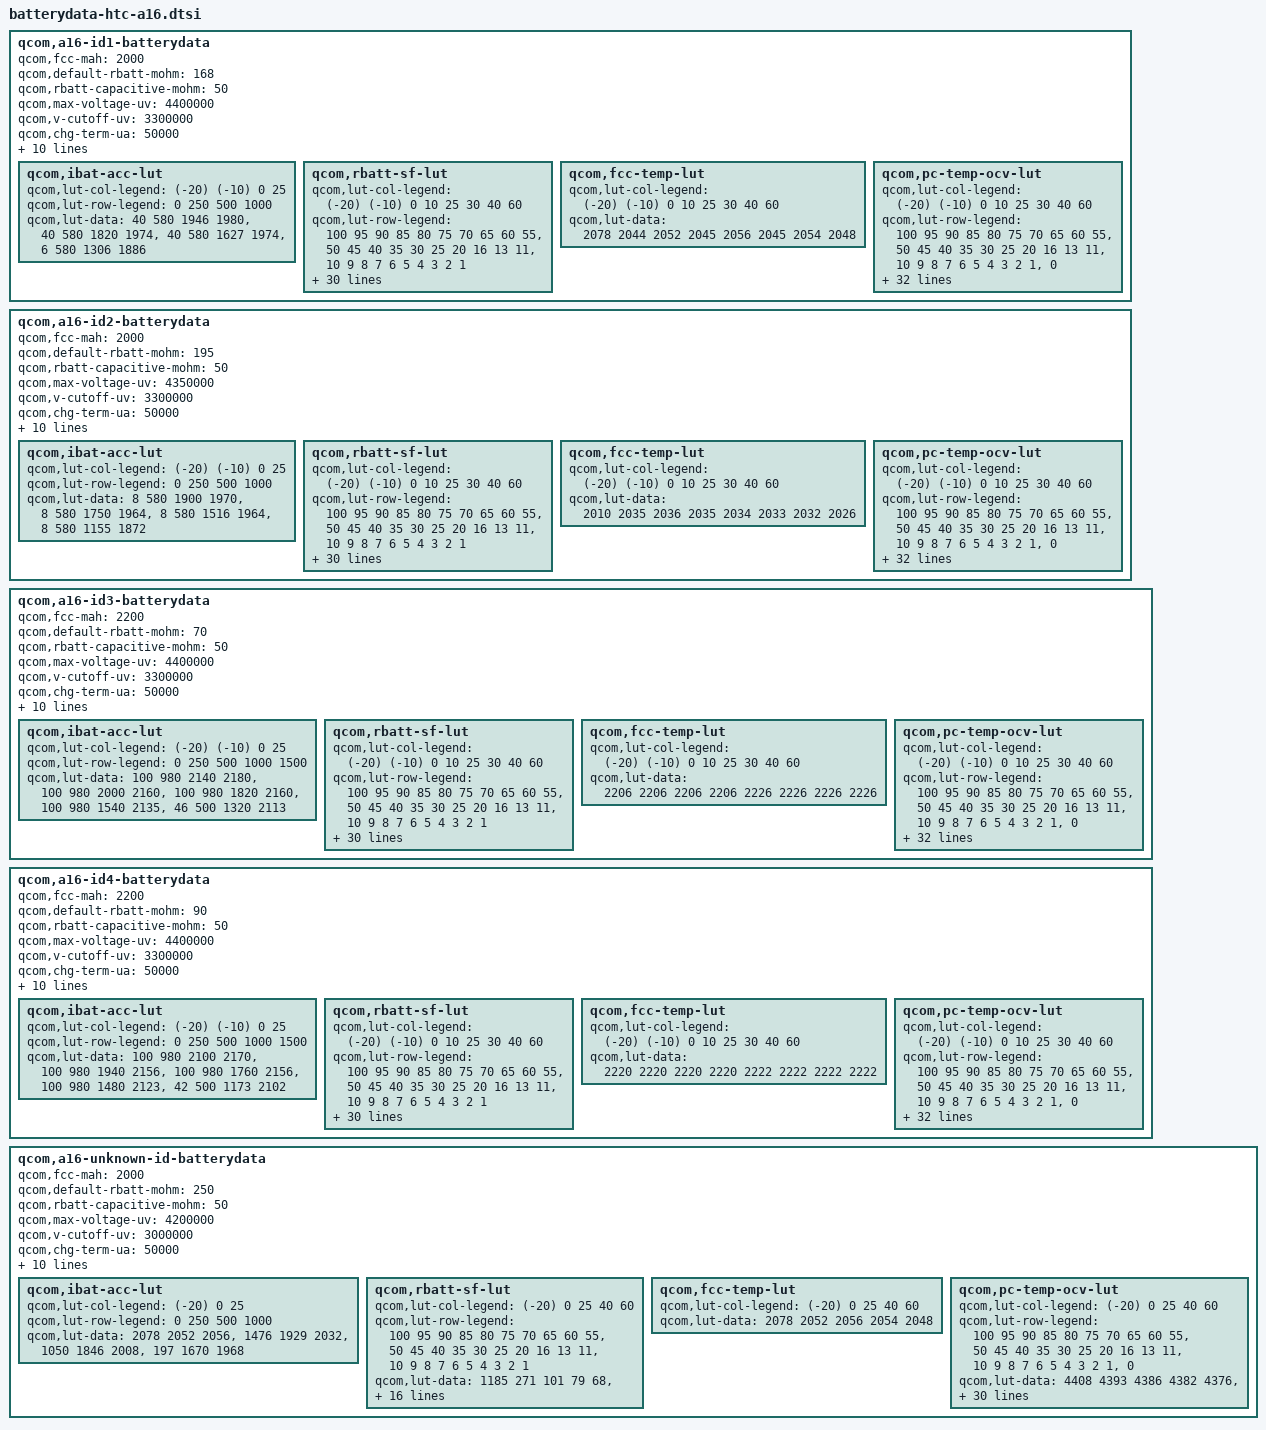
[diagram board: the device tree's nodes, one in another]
/* Copyright (c) 2016, HTC Corporation.
 * Copyright (c) 2026, The LineageOS Project.
 *
 * This program is free software; you can redistribute it and/or modify
 * it under the terms of the GNU General Public License version 2 and
 * only version 2 as published by the Free Software Foundation.
 *
 * This program is distributed in the hope that it will be useful,
 * but WITHOUT ANY WARRANTY; without even the implied warranty of
 * MERCHANTABILITY or FITNESS FOR A PARTICULAR PURPOSE.  See the
 * GNU General Public License for more details.
 */

qcom,a16-id1-batterydata {
	qcom,fcc-mah = <2000>;
	qcom,default-rbatt-mohm = <168>;
	qcom,rbatt-capacitive-mohm = <50>;
	qcom,max-voltage-uv = <4400000>;
	qcom,v-cutoff-uv = <3300000>;
	qcom,chg-term-ua = <50000>;

	qcom,batt-id-kohm = <3 9 15 20>;
	qcom,battery-type = "a16-8909-id1_2000mah";
	qcom,warm-bat-ma = <1300>;
	qcom,cool-bat-ma = <900>;
	htc,capacity = <2000>;
	htc,batt_id = <1>;
	htc,id_raw_min = <0>;
	htc,id_raw_max = <200>;
	htc,type = <1>;
	htc,model_name = "B0PKX100";

	qcom,ibat-acc-lut {
		qcom,lut-col-legend = <(-20) (-10) 0 25>;
		qcom,lut-row-legend = <0 250 500 1000>;
		qcom,lut-data = <  40  580 1946 1980>,
			<  40  580 1820 1974>,
			<  40  580 1627 1974>,
			<   6  580 1306 1886>;
	};

	qcom,rbatt-sf-lut {
		qcom,lut-col-legend = <(-20) (-10) 0 10 25 30 40 60>;
		qcom,lut-row-legend = <100  95  90  85  80  75  70  65  60  55>,
			< 50  45  40  35  30  25  20  16  13  11>,
			< 10   9   8   7   6   5   4   3   2   1>;
		qcom,lut-data = < 1185   934   271   124   101   105    79    68>,
			< 1180   933   271   124   101   105    79    68>,
			< 1074   885   276   128   102   105    80    69>,
			< 1010   830   280   131   104   104    82    71>,
			<  991   809   283   140   106   104    83    72>,
			<  955   792   299   152   110   104    86    74>,
			<  915   696   283   166   117   104    89    76>,
			<  918   695   257   160   121   105    94    79>,
			<  919   688   254   146   123   105    97    81>,
			<  947   694   250   114   105   106    88    75>,
			<  999   732   249   104    98   106    79    70>,
			< 1074   795   250   104    98   107    80    71>,
			< 1169   872   263   105    99   108    83    73>,
			< 1290   986   291   114   101   109    86    76>,
			< 1457  1128   338   132   102   110    83    75>,
			< 1812  1284   413   162   105   112    80    68>,
			< 2434  1466   520   209   108   113    82    70>,
			< 3218  1660   635   274   114   114    83    71>,
			< 3898  1864   727   344   118   115    85    71>,
			< 5040  2019   801   382   119   116    83    70>,
			< 5836  2323   868   432   124   116    85    72>,
			< 6837  2796   946   496   131   116    88    74>,
			< 8195  3410  1039   578   140   117    92    76>,
			<10071  4296  1149   686   154   118    95    77>,
			<12708  5670  1303   860   170   120    98    78>,
			<16546  7744  1611  1073   186   122    98    76>,
			<22712 11142  2169  1364   218   123   102    78>,
			<33780 18356  3195  1904   279   126   111    82>,
			<54755 32206  5193  3242   381   129   125    91>,
			<95199 60514  9269  6044   580   132   158   115>;
	};

	qcom,fcc-temp-lut {
		qcom,lut-col-legend = <(-20) (-10) 0 10 25 30 40 60>;
		qcom,lut-data = <2078 2044 2052 2045 2056 2045 2054 2048>;
	};

	qcom,pc-temp-ocv-lut {
		qcom,lut-col-legend = <(-20) (-10) 0 10 25 30 40 60>;
		qcom,lut-row-legend = <100  95  90  85  80  75  70  65  60  55>,
			< 50  45  40  35  30  25  20  16  13  11>,
			< 10   9   8   7   6   5   4   3   2   1>,
			<  0>;
		qcom,lut-data = <4408 4395 4393 4360 4360 4360 4360 4360>,
			<4287 4293 4306 4316 4315 4318 4314 4308>,
			<4204 4217 4237 4251 4253 4256 4253 4248>,
			<4132 4152 4175 4189 4192 4196 4192 4189>,
			<4074 4094 4118 4132 4134 4138 4134 4131>,
			<3998 4037 4066 4078 4080 4082 4080 4076>,
			<3926 3956 4001 4022 4028 4032 4030 4026>,
			<3882 3913 3942 3972 3978 3983 3982 3980>,
			<3842 3868 3898 3924 3935 3939 3938 3936>,
			<3820 3834 3860 3875 3883 3886 3888 3886>,
			<3806 3815 3827 3840 3846 3849 3848 3848>,
			<3793 3802 3803 3814 3820 3822 3823 3822>,
			<3781 3792 3790 3794 3800 3802 3802 3802>,
			<3768 3781 3782 3782 3784 3786 3786 3784>,
			<3753 3768 3772 3774 3771 3771 3770 3764>,
			<3736 3752 3760 3762 3758 3755 3750 3737>,
			<3717 3730 3741 3743 3738 3735 3730 3716>,
			<3698 3712 3718 3720 3717 3714 3710 3697>,
			<3681 3696 3698 3698 3696 3694 3690 3678>,
			<3666 3686 3682 3682 3683 3682 3679 3668>,
			<3657 3680 3678 3678 3680 3679 3677 3667>,
			<3646 3675 3672 3674 3678 3677 3675 3665>,
			<3634 3668 3668 3670 3674 3674 3672 3662>,
			<3620 3660 3662 3664 3670 3670 3668 3658>,
			<3600 3650 3654 3657 3661 3662 3658 3646>,
			<3572 3634 3639 3640 3637 3638 3633 3617>,
			<3532 3598 3602 3598 3593 3592 3588 3570>,
			<3474 3538 3546 3540 3534 3531 3528 3508>,
			<3394 3455 3468 3460 3453 3450 3448 3426>,
			<3274 3328 3351 3336 3333 3326 3327 3298>,
			<3000 3000 3000 3000 3000 3000 3000 3000>;
	};
};

qcom,a16-id2-batterydata {
	qcom,fcc-mah = <2000>;
	qcom,default-rbatt-mohm = <195>;
	qcom,rbatt-capacitive-mohm = <50>;
	qcom,max-voltage-uv = <4350000>;
	qcom,v-cutoff-uv = <3300000>;
	qcom,chg-term-ua = <50000>;

	qcom,batt-id-kohm = <21 25 29 33>;
	qcom,battery-type = "a16-8909-id2_2000mah";
	qcom,warm-bat-ma = <1300>;
	qcom,cool-bat-ma = <900>;
	htc,capacity = <2000>;
	htc,batt_id = <2>;
	htc,id_raw_min = <201>;
	htc,id_raw_max = <330>;
	htc,type = <1>;
	htc,model_name = "B0PKX100";

	qcom,ibat-acc-lut {
		qcom,lut-col-legend = <(-20) (-10) 0 25>;
		qcom,lut-row-legend = <0 250 500 1000>;
		qcom,lut-data = <   8  580 1900 1970>,
			<   8  580 1750 1964>,
			<   8  580 1516 1964>,
			<   8  580 1155 1872>;
	};

	qcom,rbatt-sf-lut {
		qcom,lut-col-legend = <(-20) (-10) 0 10 25 30 40 60>;
		qcom,lut-row-legend = <100  95  90  85  80  75  70  65  60  55>,
			< 50  45  40  35  30  25  20  16  13  11>,
			< 10   9   8   7   6   5   4   3   2   1>;
		qcom,lut-data = < 1138   638   323   181   100    88    76    67>,
			< 1138   638   323   181   100    88    76    67>,
			< 1069   630   326   182   101    90    77    68>,
			< 1069   617   329   186   103    91    78    69>,
			<  962   622   342   185   106    94    79    70>,
			<  943   554   339   206   111    97    82    72>,
			<  927   551   306   193   114   102    85    74>,
			<  943   546   303   190   119   106    90    77>,
			<  978   534   294   179   118   108    92    78>,
			< 1024   550   287   168   102    91    79    70>,
			< 1081   582   283   163    98    88    76    68>,
			< 1139   636   303   161    99    90    78    70>,
			< 1200   684   338   163   101    91    82    73>,
			< 1270   738   383   181   101    92    84    75>,
			< 1449   797   443   212   104    91    80    73>,
			< 1731   867   503   254   111    94    78    69>,
			< 2138   934   560   294   122    99    80    70>,
			< 2604  1000   613   324   132   107    82    69>,
			< 3047  1046   655   347   137   111    83    69>,
			< 3273  1035   660   355   136   110    85    71>,
			< 3386  1059   681   369   143   115    88    72>,
			< 3680  1087   705   385   150   119    90    74>,
			< 4026  1117   730   405   159   126    93    76>,
			< 4434  1171   757   426   168   132    96    77>,
			< 4942  1268   783   444   174   135    96    76>,
			< 5607  1411   806   456   176   135    94    74>,
			< 6570  1606   834   475   185   141    97    75>,
			< 8048  1884   875   506   198   149   102    77>,
			<11056  2318   977   547   215   161   107    81>,
			<22112  3161  1275   604   241   181   120    97>;
	};

	qcom,fcc-temp-lut {
		qcom,lut-col-legend = <(-20) (-10) 0 10 25 30 40 60>;
		qcom,lut-data = <2010 2035 2036 2035 2034 2033 2032 2026>;
	};

	qcom,pc-temp-ocv-lut {
		qcom,lut-col-legend = <(-20) (-10) 0 10 25 30 40 60>;
		qcom,lut-row-legend = <100  95  90  85  80  75  70  65  60  55>,
			< 50  45  40  35  30  25  20  16  13  11>,
			< 10   9   8   7   6   5   4   3   2   1>,
			<  0>;
		qcom,lut-data = <4340 4341 4330 4310 4310 4310 4310 4313>,
			<4202 4234 4253 4262 4268 4268 4268 4262>,
			<4124 4166 4189 4202 4210 4211 4211 4206>,
			<4088 4106 4134 4148 4156 4157 4156 4153>,
			<3972 4064 4086 4094 4104 4105 4105 4101>,
			<3925 3974 4035 4050 4058 4058 4056 4052>,
			<3878 3932 3968 3994 4006 4008 4009 4008>,
			<3851 3887 3926 3950 3966 3968 3968 3966>,
			<3833 3844 3882 3904 3922 3924 3926 3924>,
			<3816 3822 3842 3862 3873 3875 3876 3875>,
			<3800 3808 3810 3828 3840 3842 3844 3844>,
			<3784 3793 3797 3804 3816 3818 3820 3820>,
			<3768 3779 3786 3786 3796 3798 3800 3800>,
			<3752 3764 3776 3778 3780 3782 3784 3782>,
			<3734 3749 3764 3769 3768 3767 3766 3761>,
			<3716 3734 3746 3756 3755 3752 3747 3734>,
			<3694 3719 3724 3733 3733 3730 3724 3712>,
			<3673 3706 3705 3707 3705 3703 3698 3686>,
			<3651 3692 3693 3688 3685 3683 3679 3668>,
			<3633 3681 3684 3682 3680 3678 3675 3665>,
			<3623 3674 3680 3679 3678 3677 3674 3664>,
			<3610 3666 3675 3676 3676 3675 3672 3662>,
			<3594 3656 3670 3672 3673 3672 3669 3659>,
			<3574 3645 3662 3667 3668 3667 3664 3652>,
			<3550 3626 3650 3656 3656 3654 3648 3632>,
			<3516 3600 3624 3630 3626 3623 3615 3594>,
			<3470 3564 3584 3586 3580 3576 3567 3546>,
			<3408 3512 3528 3526 3518 3515 3506 3481>,
			<3320 3437 3448 3446 3436 3432 3422 3394>,
			<3208 3318 3326 3321 3310 3306 3293 3256>,
			<3000 3000 3000 3000 3000 3000 3000 3000>;
	};
};

qcom,a16-id3-batterydata {
	qcom,fcc-mah = <2200>;
	qcom,default-rbatt-mohm = <70>;
	qcom,rbatt-capacitive-mohm = <50>;
	qcom,max-voltage-uv = <4400000>;
	qcom,v-cutoff-uv = <3300000>;
	qcom,chg-term-ua = <50000>;

	qcom,batt-id-kohm = <34 38 41 44>;
	qcom,battery-type = "a16-8909-id3_2200mah";
	qcom,warm-bat-ma = <1300>;
	qcom,cool-bat-ma = <900>;
	htc,capacity = <2200>;
	htc,batt_id = <3>;
	htc,id_raw_min = <331>;
	htc,id_raw_max = <445>;
	htc,type = <1>;
	htc,model_name = "B0PKX100";

	qcom,ibat-acc-lut {
		qcom,lut-col-legend = <(-20) (-10) 0 25>;
		qcom,lut-row-legend = <0 250 500 1000 1500>;
		qcom,lut-data = < 100  980 2140 2180>,
			< 100  980 2000 2160>,
			< 100  980 1820 2160>,
			< 100  980 1540 2135>,
			<  46  500 1320 2113>;
	};

	qcom,rbatt-sf-lut {
		qcom,lut-col-legend = <(-20) (-10) 0 10 25 30 40 60>;
		qcom,lut-row-legend = <100  95  90  85  80  75  70  65  60  55>,
			< 50  45  40  35  30  25  20  16  13  11>,
			< 10   9   8   7   6   5   4   3   2   1>;
		qcom,lut-data = <1174  536  244  161  100   95   83   76>,
			<1174  536  244  161  100   95   83   76>,
			<1103  541  245  161  101   96   84   77>,
			<1043  545  246  163  103   97   85   78>,
			<1012  544  251  167  106  100   88   80>,
			< 987  562  256  172  109  103   90   81>,
			< 898  545  272  187  116  109   94   83>,
			< 897  492  247  188  122  114   99   86>,
			< 889  497  230  177  130  122  105   90>,
			< 899  494  223  156  107  100   91   82>,
			< 920  493  221  152   99   95   84   78>,
			< 945  511  222  153  100   96   85   78>,
			< 978  536  226  155  102   99   87   80>,
			<1014  565  232  158  106  102   91   84>,
			<1061  598  244  162  107  103   92   85>,
			<1121  637  260  168  103   97   86   79>,
			<1196  677  275  170  101   97   84   78>,
			<1275  725  286  174  103   97   86   78>,
			<1333  781  296  176  103   97   85   78>,
			<1278  804  290  176  100   96   83   76>,
			<1321  788  297  173  101   97   84   78>,
			<1370  816  307  177  103   98   87   79>,
			<1426  850  326  182  106  100   88   82>,
			<1497  892  344  190  109  104   91   86>,
			<1665  937  366  200  113  107   95   87>,
			<1943  986  388  204  111  105   90   82>,
			<2357 1043  402  203  108  102   89   80>,
			<2993 1126  444  216  111  104   90   83>,
			<4021 1329  511  236  116  111   97   88>,
			<6863 2495  694  309  154  151  134  107>;
	};

	qcom,fcc-temp-lut {
		qcom,lut-col-legend = <(-20) (-10) 0 10 25 30 40 60>;
		qcom,lut-data = <2206 2206 2206 2206 2226 2226 2226 2226>;
	};

	qcom,pc-temp-ocv-lut {
		qcom,lut-col-legend = <(-20) (-10) 0 10 25 30 40 60>;
		qcom,lut-row-legend = <100  95  90  85  80  75  70  65  60  55>,
			< 50  45  40  35  30  25  20  16  13  11>,
			< 10   9   8   7   6   5   4   3   2   1>,
			<  0>;
		qcom,lut-data = <4360 4360 4360 4360 4360 4360 4360 4360>,
			<4294 4313 4322 4315 4315 4315 4315 4315>,
			<4220 4248 4260 4260 4260 4260 4260 4260>,
			<4156 4190 4202 4210 4208 4212 4207 4204>,
			<4105 4134 4148 4156 4152 4156 4151 4148>,
			<4052 4086 4096 4102 4098 4102 4097 4095>,
			<3960 4024 4046 4056 4049 4054 4048 4045>,
			<3917 3947 3973 3993 3998 4004 4000 4000>,
			<3874 3908 3926 3946 3956 3962 3958 3956>,
			<3844 3870 3886 3896 3900 3902 3902 3901>,
			<3824 3836 3854 3860 3862 3864 3864 3864>,
			<3806 3815 3826 3833 3834 3838 3836 3836>,
			<3790 3800 3805 3811 3814 3816 3814 3814>,
			<3775 3786 3789 3792 3794 3796 3796 3796>,
			<3760 3772 3777 3778 3778 3780 3778 3776>,
			<3744 3757 3765 3766 3761 3758 3754 3743>,
			<3729 3734 3748 3748 3740 3738 3732 3719>,
			<3716 3717 3726 3726 3720 3717 3712 3699>,
			<3705 3706 3707 3705 3700 3698 3692 3680>,
			<3696 3698 3698 3694 3690 3688 3682 3672>,
			<3690 3694 3694 3692 3688 3686 3682 3670>,
			<3682 3690 3692 3690 3688 3685 3680 3669>,
			<3673 3684 3689 3688 3686 3684 3680 3668>,
			<3662 3677 3686 3686 3684 3680 3676 3665>,
			<3646 3665 3680 3680 3678 3674 3670 3656>,
			<3621 3644 3664 3660 3658 3652 3645 3628>,
			<3586 3606 3624 3618 3614 3607 3599 3582>,
			<3538 3552 3566 3558 3555 3547 3540 3524>,
			<3466 3474 3487 3477 3474 3466 3459 3444>,
			<3350 3348 3366 3351 3356 3340 3337 3324>,
			<3000 3000 3000 3000 3000 3000 3000 3000>;
	};
};

qcom,a16-id4-batterydata {
	qcom,fcc-mah = <2200>;
	qcom,default-rbatt-mohm = <90>;
	qcom,rbatt-capacitive-mohm = <50>;
	qcom,max-voltage-uv = <4400000>;
	qcom,v-cutoff-uv = <3300000>;
	qcom,chg-term-ua = <50000>;

	qcom,batt-id-kohm = <45 50 55 60>;
	qcom,battery-type = "a16-8909-id4_2200mah";
	qcom,warm-bat-ma = <1300>;
	qcom,cool-bat-ma = <900>;
	htc,capacity = <2200>;
	htc,batt_id = <4>;
	htc,id_raw_min = <446>;
	htc,id_raw_max = <600>;
	htc,type = <1>;
	htc,model_name = "B0PKX100";

	qcom,ibat-acc-lut {
		qcom,lut-col-legend = <(-20) (-10) 0 25>;
		qcom,lut-row-legend = <0 250 500 1000 1500>;
		qcom,lut-data = < 100  980 2100 2170>,
			< 100  980 1940 2156>,
			< 100  980 1760 2156>,
			< 100  980 1480 2123>,
			<  42  500 1173 2102>;
	};

	qcom,rbatt-sf-lut {
		qcom,lut-col-legend = <(-20) (-10) 0 10 25 30 40 60>;
		qcom,lut-row-legend = <100  95  90  85  80  75  70  65  60  55>,
			< 50  45  40  35  30  25  20  16  13  11>,
			< 10   9   8   7   6   5   4   3   2   1>;
		qcom,lut-data = <1093  487  273  160  100   89   79   73>,
			<1091  487  273  160  100   89   79   73>,
			<1024  485  271  160   99   89   79   73>,
			< 983  484  266  159  101   90   81   74>,
			< 955  483  267  160  102   91   82   75>,
			< 855  504  274  164  106   94   85   77>,
			< 836  475  280  174  110   97   87   79>,
			< 823  441  249  171  115  101   91   81>,
			< 831  434  235  173  119  107   96   84>,
			< 854  427  226  151  108   99   92   83>,
			< 896  431  223  141   95   88   80   74>,
			< 935  450  226  141   95   87   79   74>,
			< 977  474  233  145   96   90   82   77>,
			<1026  503  248  148   99   93   86   79>,
			<1095  539  271  153  102   94   86   80>,
			<1156  577  301  160  102   92   82   75>,
			<1226  611  326  168  100   89   81   74>,
			<1281  642  335  170  101   89   81   74>,
			<1259  670  338  173   97   87   78   72>,
			<1224  662  351  174   98   89   79   74>,
			<1254  667  363  177  101   90   81   75>,
			<1288  682  377  182  105   92   83   77>,
			<1364  701  394  191  107   94   85   79>,
			<1500  719  413  199  113   98   88   82>,
			<1661  738  427  206  115   99   89   81>,
			<1875  750  434  207  111   95   86   78>,
			<2173  767  447  206  112   95   85   78>,
			<2633  794  475  213  115   98   87   80>,
			<3538  839  517  229  126  107   97   92>,
			<7075 1307  678  530  165  139  134  112>;
	};

	qcom,fcc-temp-lut {
		qcom,lut-col-legend = <(-20) (-10) 0 10 25 30 40 60>;
		qcom,lut-data = <2220 2220 2220 2220 2222 2222 2222 2222>;
	};

	qcom,pc-temp-ocv-lut {
		qcom,lut-col-legend = <(-20) (-10) 0 10 25 30 40 60>;
		qcom,lut-row-legend = <100  95  90  85  80  75  70  65  60  55>,
			< 50  45  40  35  30  25  20  16  13  11>,
			< 10   9   8   7   6   5   4   3   2   1>,
			<  0>;
		qcom,lut-data = <4360 4360 4360 4360 4360 4360 4360 4360>,
			<4262 4299 4306 4319 4315 4322 4314 4310>,
			<4176 4232 4243 4260 4256 4266 4256 4251>,
			<4116 4171 4185 4203 4200 4208 4199 4195>,
			<4065 4116 4132 4150 4145 4154 4144 4141>,
			<3968 4076 4082 4098 4092 4102 4092 4089>,
			<3920 4012 4032 4054 4044 4054 4043 4040>,
			<3876 3947 3966 3995 3994 4006 3998 3996>,
			<3848 3900 3920 3954 3954 3964 3956 3954>,
			<3828 3860 3879 3902 3904 3914 3909 3908>,
			<3810 3832 3845 3862 3862 3870 3864 3864>,
			<3792 3814 3819 3833 3833 3840 3836 3836>,
			<3776 3800 3799 3812 3811 3818 3814 3814>,
			<3758 3788 3786 3792 3793 3798 3796 3794>,
			<3743 3774 3776 3779 3778 3782 3778 3774>,
			<3728 3756 3764 3768 3764 3763 3758 3748>,
			<3716 3732 3742 3748 3744 3739 3735 3722>,
			<3706 3712 3715 3719 3716 3712 3709 3696>,
			<3695 3700 3698 3698 3692 3690 3684 3674>,
			<3684 3692 3692 3692 3688 3685 3680 3670>,
			<3676 3688 3688 3689 3686 3684 3680 3668>,
			<3668 3682 3686 3687 3685 3683 3678 3668>,
			<3658 3676 3682 3685 3684 3682 3678 3666>,
			<3644 3668 3678 3682 3680 3678 3674 3662>,
			<3624 3654 3666 3673 3672 3670 3666 3652>,
			<3594 3627 3637 3650 3646 3643 3640 3620>,
			<3551 3584 3586 3604 3600 3596 3592 3572>,
			<3486 3522 3517 3541 3534 3530 3528 3508>,
			<3392 3434 3417 3454 3446 3444 3442 3424>,
			<3256 3296 3267 3312 3314 3322 3314 3298>,
			<3000 3000 3000 3000 3000 3000 3000 3000>;
	};
};

qcom,a16-unknown-id-batterydata {
	qcom,fcc-mah = <2000>;
	qcom,default-rbatt-mohm = <250>;
	qcom,rbatt-capacitive-mohm = <50>;
	qcom,max-voltage-uv = <4200000>;
	qcom,v-cutoff-uv = <3000000>;
	qcom,chg-term-ua = <50000>;

	qcom,batt-id-kohm = <63 75 90 99>;
	qcom,battery-type = "a16-8909-unknown_2000mah";
	qcom,warm-bat-ma = <1300>;
	qcom,cool-bat-ma = <900>;
	htc,capacity = <2000>;
	htc,batt_id = <255>;
	htc,id_raw_min = <(-1)>;
	htc,id_raw_max = <(-1)>;
	htc,type = <0>;
	htc,model_name = "UNKNOWN";

	qcom,ibat-acc-lut {
		qcom,lut-col-legend = <(-20) 0 25>;
		qcom,lut-row-legend = <0 250 500 1000>;
		qcom,lut-data = <2078 2052 2056>,
			<1476 1929 2032>,
			<1050 1846 2008>,
			< 197 1670 1968>;
	};

	qcom,rbatt-sf-lut {
		qcom,lut-col-legend = <(-20) 0 25 40 60>;
		qcom,lut-row-legend = <100  95  90  85  80  75  70  65  60  55>,
			< 50  45  40  35  30  25  20  16  13  11>,
			< 10   9   8   7   6   5   4   3   2   1>;
		qcom,lut-data = < 1185   271   101    79    68>,
			< 1180   271   101    79    68>,
			< 1074   276   102    80    69>,
			< 1010   280   104    82    71>,
			<  991   283   106    83    72>,
			<  955   299   110    86    74>,
			<  915   283   117    89    76>,
			<  918   257   121    94    79>,
			<  919   254   123    97    81>,
			<  947   250   105    88    75>,
			<  999   249    98    79    70>,
			< 1074   250    98    80    71>,
			< 1169   263    99    83    73>,
			< 1290   291   101    86    76>,
			< 1457   338   102    83    75>,
			< 1812   413   105    80    68>,
			< 2434   520   108    82    70>,
			< 3218   635   114    83    71>,
			< 3898   727   118    85    71>,
			< 5040   801   119    83    70>,
			< 5836   868   124    85    72>,
			< 6837   946   131    88    74>,
			< 8195  1039   140    92    76>,
			<10071  1149   154    95    77>,
			<12708  1303   170    98    78>,
			<16546  1611   186    98    76>,
			<22712  2169   218   102    78>,
			<33780  3195   279   111    82>,
			<54755  5193   381   125    91>,
			<95199  9269   580   158   115>;
	};

	qcom,fcc-temp-lut {
		qcom,lut-col-legend = <(-20) 0 25 40 60>;
		qcom,lut-data = <2078 2052 2056 2054 2048>;
	};

	qcom,pc-temp-ocv-lut {
		qcom,lut-col-legend = <(-20) 0 25 40 60>;
		qcom,lut-row-legend = <100  95  90  85  80  75  70  65  60  55>,
			< 50  45  40  35  30  25  20  16  13  11>,
			< 10   9   8   7   6   5   4   3   2   1>,
			<  0>;
		qcom,lut-data = <4408 4393 4386 4382 4376>,
			<4287 4306 4315 4314 4308>,
			<4204 4237 4253 4253 4248>,
			<4132 4175 4192 4192 4189>,
			<4074 4118 4134 4134 4131>,
			<3998 4066 4080 4080 4076>,
			<3926 4001 4028 4030 4026>,
			<3882 3942 3978 3982 3980>,
			<3842 3898 3935 3938 3936>,
			<3820 3860 3883 3888 3886>,
			<3806 3827 3846 3848 3848>,
			<3793 3803 3820 3823 3822>,
			<3781 3790 3800 3802 3802>,
			<3768 3782 3784 3786 3784>,
			<3753 3772 3771 3770 3764>,
			<3736 3760 3758 3750 3737>,
			<3717 3741 3738 3730 3716>,
			<3698 3718 3717 3710 3697>,
			<3681 3698 3696 3690 3678>,
			<3666 3682 3683 3679 3668>,
			<3657 3678 3680 3677 3667>,
			<3646 3672 3678 3675 3665>,
			<3634 3668 3674 3672 3662>,
			<3620 3662 3670 3668 3658>,
			<3600 3654 3661 3658 3646>,
			<3572 3639 3637 3633 3617>,
			<3532 3602 3593 3588 3570>,
			<3474 3546 3534 3528 3508>,
			<3394 3468 3453 3448 3426>,
			<3274 3351 3333 3327 3298>,
			<3000 3000 3000 3000 3000>;
	};
};
